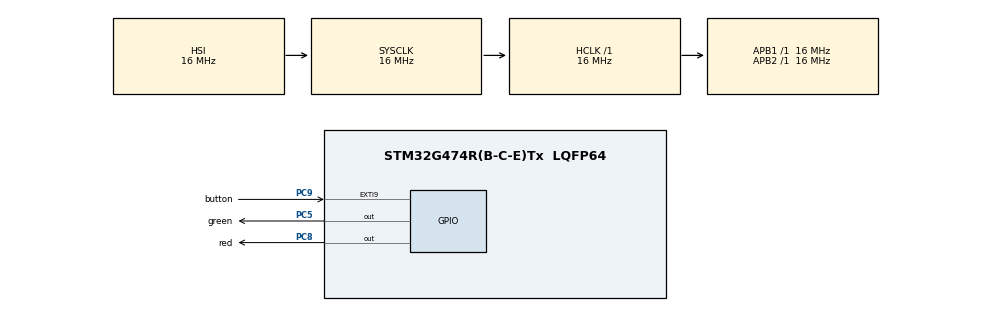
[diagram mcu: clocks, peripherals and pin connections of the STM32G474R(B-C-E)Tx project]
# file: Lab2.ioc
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Mcu.Family=STM32G4
Mcu.Name=STM32G474R(B-C-E)Tx
Mcu.Package=LQFP64
NVIC.EXTI9_5_IRQn=true\:1\:0\:true\:false\:true\:true\:true\:true
NVIC.PriorityGroup=NVIC_PRIORITYGROUP_4
PC5.GPIO_Label=green
PC5.Signal=GPIO_Output
PC8.GPIO_Label=red
PC8.Signal=GPIO_Output
PC9.GPIO_Label=button
PC9.GPIO_ModeDefaultEXTI=GPIO_MODE_IT_FALLING
PC9.GPIO_PuPd=GPIO_PULLUP
PC9.Signal=GPXTI9
ProjectManager.HeapSize=0x200
ProjectManager.StackSize=0x400
ProjectManager.TargetToolchain=STM32CubeIDE
RCC.AHBFreq_Value=16000000
RCC.APB1Freq_Value=16000000
RCC.APB1TimFreq_Value=16000000
RCC.APB2Freq_Value=16000000
RCC.APB2TimFreq_Value=16000000
RCC.CortexFreq_Value=16000000
RCC.EXTERNAL_CLOCK_VALUE=12288000
RCC.HCLKFreq_Value=16000000
RCC.HSE_VALUE=8000000
RCC.HSI48_VALUE=48000000
RCC.HSI_VALUE=16000000
RCC.LSE_VALUE=32768
RCC.SYSCLKFreq_VALUE=16000000
RCC.USBFreq_Value=64000000
RCC.VCOOutputFreq_Value=128000000
VP_SYS_VS_DBSignals.Mode=DisableDeadBatterySignals
board=custom

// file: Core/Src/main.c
/* USER CODE BEGIN Header */
/**
  ******************************************************************************
  * @file           : main.c
  * @brief          : Main program body
  ******************************************************************************
  * @attention
  *
  * Copyright (c) 2026 STMicroelectronics.
  * All rights reserved.
  *
  * This software is licensed under terms that can be found in the LICENSE file
  * in the root directory of this software component.
  * If no LICENSE file comes with this software, it is provided AS-IS.
  *
  ******************************************************************************
  */
/* USER CODE END Header */
#include "main.h"

/* USER CODE BEGIN PV */
volatile uint8_t led_mode = 0;
volatile uint8_t led_is_on = 0;
/* USER CODE END PV */

void SystemClock_Config(void);
static void MX_GPIO_Init(void);

int main(void)
{

  /* MCU Configuration--------------------------------------------------------*/

  /* Reset of all peripherals, Initializes the Flash interface and the Systick. */
  HAL_Init();

  /* Configure the system clock */
  SystemClock_Config();

  /* Initialize all configured peripherals */
  MX_GPIO_Init();

  /* Infinite loop */
  /* USER CODE BEGIN WHILE */
  while (1)
  {
    /* USER CODE BEGIN 3 */
	    uint32_t blink_time = (led_mode == 0) ? 2000 : 500;

    //LED點亮
    led_is_on = 1;

    if(led_mode == 0){
        //G亮R暗
        HAL_GPIO_WritePin(green_GPIO_Port, green_Pin, GPIO_PIN_SET);
        HAL_GPIO_WritePin(red_GPIO_Port, red_Pin, GPIO_PIN_RESET);
    }
    else{
        HAL_GPIO_WritePin(green_GPIO_Port, green_Pin, GPIO_PIN_RESET);
        HAL_GPIO_WritePin(red_GPIO_Port, red_Pin, GPIO_PIN_SET);
    }

    HAL_Delay(blink_time);

    //熄滅階段
    led_is_on = 0;
    HAL_GPIO_WritePin(green_GPIO_Port, green_Pin, GPIO_PIN_RESET);
    HAL_GPIO_WritePin(red_GPIO_Port, red_Pin, GPIO_PIN_RESET);
    HAL_Delay(2000);
  }
  /* USER CODE END 3 */
}/* USER CODE END WHILE */

void SystemClock_Config(void)
{
  RCC_OscInitTypeDef RCC_OscInitStruct = {0};
  RCC_ClkInitTypeDef RCC_ClkInitStruct = {0};

  /** Configure the main internal regulator output voltage
  */
  HAL_PWREx_ControlVoltageScaling(PWR_REGULATOR_VOLTAGE_SCALE1);

  /** Initializes the RCC Oscillators according to the specified parameters
  * in the RCC_OscInitTypeDef structure.
  */
  RCC_OscInitStruct.OscillatorType = RCC_OSCILLATORTYPE_HSI;
  RCC_OscInitStruct.HSIState = RCC_HSI_ON;
  RCC_OscInitStruct.HSICalibrationValue = RCC_HSICALIBRATION_DEFAULT;
  RCC_OscInitStruct.PLL.PLLState = RCC_PLL_NONE;
  if (HAL_RCC_OscConfig(&RCC_OscInitStruct) != HAL_OK)
  {
    Error_Handler();
  }

  /** Initializes the CPU, AHB and APB buses clocks
  */
  RCC_ClkInitStruct.ClockType = RCC_CLOCKTYPE_HCLK|RCC_CLOCKTYPE_SYSCLK
                              |RCC_CLOCKTYPE_PCLK1|RCC_CLOCKTYPE_PCLK2;
  RCC_ClkInitStruct.SYSCLKSource = RCC_SYSCLKSOURCE_HSI;
  RCC_ClkInitStruct.AHBCLKDivider = RCC_SYSCLK_DIV1;
  RCC_ClkInitStruct.APB1CLKDivider = RCC_HCLK_DIV1;
  RCC_ClkInitStruct.APB2CLKDivider = RCC_HCLK_DIV1;

  if (HAL_RCC_ClockConfig(&RCC_ClkInitStruct, FLASH_LATENCY_0) != HAL_OK)
  {
    Error_Handler();
  }
}

static void MX_GPIO_Init(void)
{
  GPIO_InitTypeDef GPIO_InitStruct = {0};

  /* GPIO Ports Clock Enable */
  __HAL_RCC_GPIOC_CLK_ENABLE();

  /*Configure GPIO pin Output Level */
  HAL_GPIO_WritePin(GPIOC, green_Pin|red_Pin, GPIO_PIN_RESET);

  /*Configure GPIO pins : green_Pin red_Pin */
  GPIO_InitStruct.Pin = green_Pin|red_Pin;
  GPIO_InitStruct.Mode = GPIO_MODE_OUTPUT_PP;
  GPIO_InitStruct.Pull = GPIO_NOPULL;
  GPIO_InitStruct.Speed = GPIO_SPEED_FREQ_LOW;
  HAL_GPIO_Init(GPIOC, &GPIO_InitStruct);

  /*Configure GPIO pin : button_Pin */
  GPIO_InitStruct.Pin = button_Pin;
  GPIO_InitStruct.Mode = GPIO_MODE_IT_FALLING;
  GPIO_InitStruct.Pull = GPIO_PULLUP;
  HAL_GPIO_Init(button_GPIO_Port, &GPIO_InitStruct);

  /* EXTI interrupt init*/
  HAL_NVIC_SetPriority(EXTI9_5_IRQn, 1, 0);
  HAL_NVIC_EnableIRQ(EXTI9_5_IRQn);

}

/* USER CODE BEGIN 4 */
/* USER CODE BEGIN 4 */
void HAL_GPIO_EXTI_Callback(uint16_t GPIO_Pin){
	HAL_Delay(50);
	if(GPIO_Pin == button_Pin){
		//每按一次，綠紅切換
		if (led_mode == 0)
			led_mode = 1;
		else
			led_mode = 0;

		if(led_is_on == 1){
			if(led_mode == 0){
				//換綠色
				HAL_GPIO_WritePin(green_GPIO_Port,green_Pin,GPIO_PIN_SET);
				HAL_GPIO_WritePin(red_GPIO_Port,red_Pin,GPIO_PIN_RESET);
			}
			else{ //換紅色
				HAL_GPIO_WritePin(green_GPIO_Port,green_Pin,GPIO_PIN_RESET);
				HAL_GPIO_WritePin(red_GPIO_Port,red_Pin,GPIO_PIN_SET);
			}
		}
	} // <-- 補上這一個（對應 if(GPIO_Pin == button_Pin)）
}   // <-- 補上這一個（對應 void HAL_GPIO_EXTI_Callback）
/* USER CODE END 4 */

void Error_Handler(void)
{
  __disable_irq();
  while (1)
  {
  }
}
